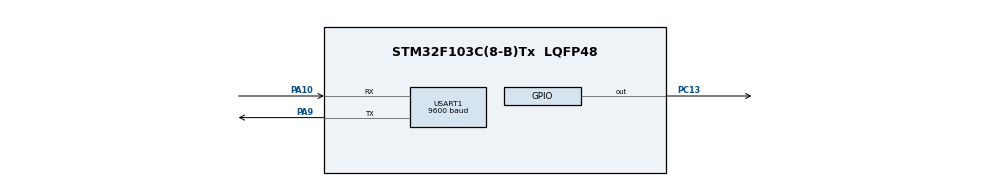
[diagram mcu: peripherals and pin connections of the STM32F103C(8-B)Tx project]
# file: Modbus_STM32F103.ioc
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Mcu.Family=STM32F1
Mcu.Name=STM32F103C(8-B)Tx
Mcu.Package=LQFP48
NVIC.PriorityGroup=NVIC_PRIORITYGROUP_4
NVIC.USART1_IRQn=true\:0\:0\:false\:false\:true\:true\:true\:true
PA10.Mode=Asynchronous
PA10.Signal=USART1_RX
PA13.Mode=Serial_Wire
PA13.Signal=SYS_JTMS-SWDIO
PA14.Mode=Serial_Wire
PA14.Signal=SYS_JTCK-SWCLK
PA9.Mode=Asynchronous
PA9.Signal=USART1_TX
PC13-TAMPER-RTC.Signal=GPIO_Output
PD0-OSC_IN.Mode=HSE-External-Oscillator
PD0-OSC_IN.Signal=RCC_OSC_IN
PD1-OSC_OUT.Mode=HSE-External-Oscillator
PD1-OSC_OUT.Signal=RCC_OSC_OUT
ProjectManager.HeapSize=0x200
ProjectManager.StackSize=0x400
ProjectManager.TargetToolchain=STM32CubeIDE
RCC.APB1Freq_Value=8000000
RCC.APB2Freq_Value=8000000
USART1.BaudRate=9600
USART1.VirtualMode=VM_ASYNC
board=custom

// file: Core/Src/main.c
/* USER CODE BEGIN Header */
/**
  ******************************************************************************
  * @file           : main.c
  * @brief          : Main program body
  ******************************************************************************
  * @attention
  *
  * Copyright (c) 2026 STMicroelectronics.
  * All rights reserved.
  *
  * This software is licensed under terms that can be found in the LICENSE file
  * in the root directory of this software component.
  * If no LICENSE file comes with this software, it is provided AS-IS.
  *
  ******************************************************************************
  */
/* USER CODE END Header */
#include "main.h"

UART_HandleTypeDef huart1;

void SystemClock_Config(void);
static void MX_GPIO_Init(void);
static void MX_USART1_UART_Init(void);

/* USER CODE BEGIN 0 */
uint8_t rx_buf[64];//串口接收缓冲区，用来存放 NT1-B 转发过来的 Modbus 请求数据。

uint16_t sand_type = 3;//模拟砂石种类，对应寄存器地址 0x0010，也就是 MThings 里面的地址 16。
uint16_t moisture = 128;//模拟水分值，对应寄存器地址 0x0011，也就是地址 17。这里设置为 128，表示水分值 12.8%，因为协议规定实际值要乘以 10 存储。

uint16_t Modbus_CRC16(uint8_t *buf, uint16_t len)
{
    uint16_t crc = 0xFFFF;

    for (uint16_t pos = 0; pos < len; pos++)
    {
        crc ^= buf[pos];

        for (uint8_t i = 0; i < 8; i++)
        {
            if (crc & 0x0001)
            {
                crc >>= 1;
                crc ^= 0xA001;
            }
            else
            {
                crc >>= 1;
            }
        }
    }

    return crc;
}//计算 Modbus RTU 的 CRC16 校验码。
//CRC 的作用是检查数据在传输过程中有没有出错。
/* USER CODE END 0 */

int main(void)
{

  /* MCU Configuration--------------------------------------------------------*/

  /* Reset of all peripherals, Initializes the Flash interface and the Systick. */
  HAL_Init();

  /* Configure the system clock */
  SystemClock_Config();

  /* Initialize all configured peripherals */
  MX_GPIO_Init();
  MX_USART1_UART_Init();
  /* USER CODE BEGIN 2 */
  uint8_t msg[] = "USART1 OK\r\n";
  HAL_UART_Transmit(&huart1, msg, sizeof(msg)-1, 1000);
  /* USER CODE END 2 */

  /* Infinite loop */
  while (1)
  {
	  if (HAL_UART_Receive(&huart1, rx_buf, 8, 100) == HAL_OK)//通过 USART1 接收串口数据//huart1 对应 STM32 的 USART1，也就是 PA9、PA10
		  //rx_buf 是接收缓冲区//8 表示这里按 8 字节接收一帧常见的 Modbus 请求。100 是超时时间，避免程序一直卡死在接收函数里。
	     {
	         // 06：写单个寄存器
	         if (rx_buf[1] == 0x06)//rx_buf[1] 是功能码。
	         {
	             // 写地址 0x0010，也就是砂石种类
	             if (rx_buf[2] == 0x00 && rx_buf[3] == 0x10)
	             {
	                 sand_type = ((uint16_t)rx_buf[4] << 8) | rx_buf[5];//高字节和低字节合并成一个 16 位整数
	             }

	             // 写成功后，原样返回
	             HAL_UART_Transmit(&huart1, rx_buf, 8, 1000);
	         }

	         // 03：读寄存器
	         else if (rx_buf[1] == 0x03)//如果功能码是 0x03，说明上位机要读取保持寄存器。
	         {
	             uint8_t response[9];//构造了一个 9 字节的响应帧。

	             response[0] = 0x01;//从机地址是 1。
	             response[1] = 0x03;//表示响应的是读保持寄存器功能。
	             response[2] = 0x04;//表示后面有 4 个字节的数据，因为读取了两个寄存器，每个寄存器 2 字节。

	             response[3] = sand_type >> 8;
	             response[4] = sand_type & 0xFF;//把砂石种类拆成高字节和低字节。

	             response[5] = moisture >> 8;
	             response[6] = moisture & 0xFF;//把水分值拆成高字节和低字节。

	             uint16_t crc = Modbus_CRC16(response, 7);
	             response[7] = crc & 0xFF;
	             response[8] = crc >> 8;//计算 CRC

	             HAL_UART_Transmit(&huart1, response, 9, 1000);//最后发送响应
	         }

	         HAL_GPIO_TogglePin(GPIOC, GPIO_PIN_13);
	     }
  }
}

void SystemClock_Config(void)
{
  RCC_OscInitTypeDef RCC_OscInitStruct = {0};
  RCC_ClkInitTypeDef RCC_ClkInitStruct = {0};

  /** Initializes the RCC Oscillators according to the specified parameters
  * in the RCC_OscInitTypeDef structure.
  */
  RCC_OscInitStruct.OscillatorType = RCC_OSCILLATORTYPE_HSI;
  RCC_OscInitStruct.HSIState = RCC_HSI_ON;
  RCC_OscInitStruct.HSICalibrationValue = RCC_HSICALIBRATION_DEFAULT;
  RCC_OscInitStruct.PLL.PLLState = RCC_PLL_NONE;
  if (HAL_RCC_OscConfig(&RCC_OscInitStruct) != HAL_OK)
  {
    Error_Handler();
  }

  /** Initializes the CPU, AHB and APB buses clocks
  */
  RCC_ClkInitStruct.ClockType = RCC_CLOCKTYPE_HCLK|RCC_CLOCKTYPE_SYSCLK
                              |RCC_CLOCKTYPE_PCLK1|RCC_CLOCKTYPE_PCLK2;
  RCC_ClkInitStruct.SYSCLKSource = RCC_SYSCLKSOURCE_HSI;
  RCC_ClkInitStruct.AHBCLKDivider = RCC_SYSCLK_DIV1;
  RCC_ClkInitStruct.APB1CLKDivider = RCC_HCLK_DIV1;
  RCC_ClkInitStruct.APB2CLKDivider = RCC_HCLK_DIV1;

  if (HAL_RCC_ClockConfig(&RCC_ClkInitStruct, FLASH_LATENCY_0) != HAL_OK)
  {
    Error_Handler();
  }
}

static void MX_USART1_UART_Init(void)
{

  huart1.Instance = USART1;
  huart1.Init.BaudRate = 9600;
  huart1.Init.WordLength = UART_WORDLENGTH_8B;
  huart1.Init.StopBits = UART_STOPBITS_1;
  huart1.Init.Parity = UART_PARITY_NONE;
  huart1.Init.Mode = UART_MODE_TX_RX;
  huart1.Init.HwFlowCtl = UART_HWCONTROL_NONE;
  huart1.Init.OverSampling = UART_OVERSAMPLING_16;
  if (HAL_UART_Init(&huart1) != HAL_OK)
  {
    Error_Handler();
  }

}

static void MX_GPIO_Init(void)
{
  GPIO_InitTypeDef GPIO_InitStruct = {0};

  /* GPIO Ports Clock Enable */
  __HAL_RCC_GPIOC_CLK_ENABLE();
  __HAL_RCC_GPIOD_CLK_ENABLE();
  __HAL_RCC_GPIOA_CLK_ENABLE();

  /*Configure GPIO pin Output Level */
  HAL_GPIO_WritePin(GPIOC, GPIO_PIN_13, GPIO_PIN_RESET);

  /*Configure GPIO pin : PC13 */
  GPIO_InitStruct.Pin = GPIO_PIN_13;
  GPIO_InitStruct.Mode = GPIO_MODE_OUTPUT_PP;
  GPIO_InitStruct.Pull = GPIO_NOPULL;
  GPIO_InitStruct.Speed = GPIO_SPEED_FREQ_LOW;
  HAL_GPIO_Init(GPIOC, &GPIO_InitStruct);

}

void Error_Handler(void)
{
  __disable_irq();
  while (1)
  {
  }
}
